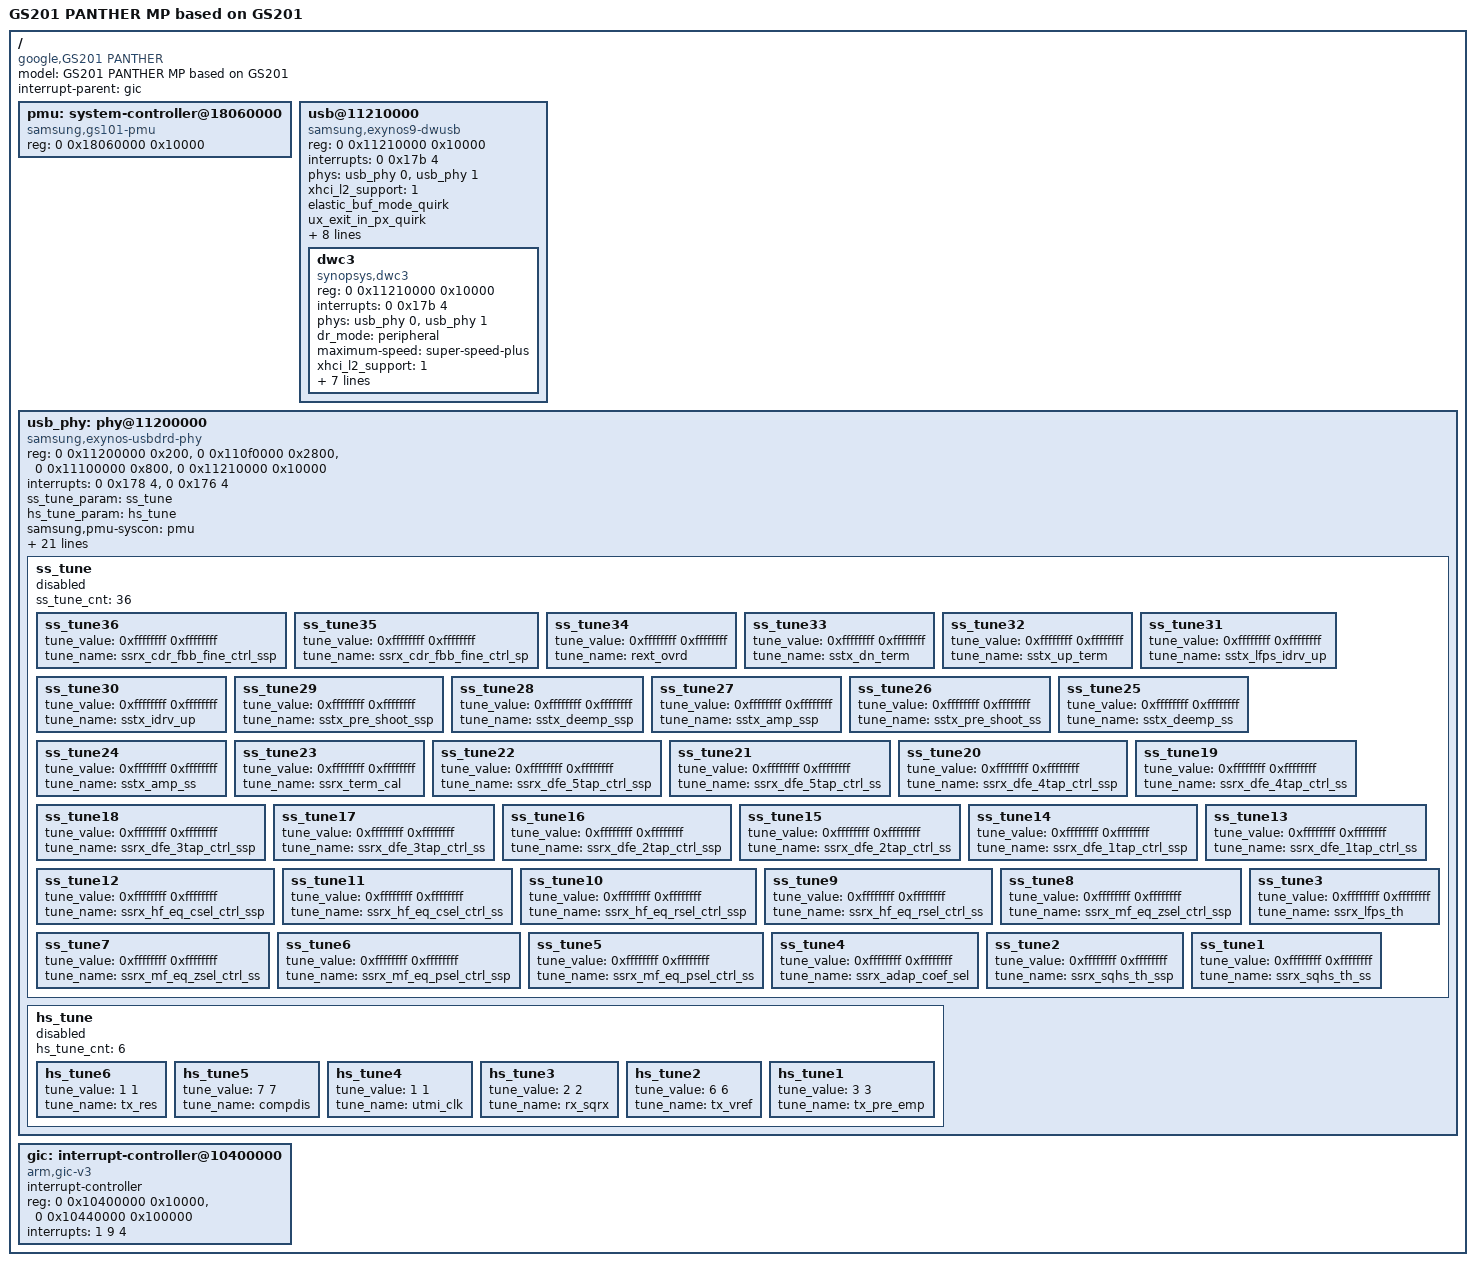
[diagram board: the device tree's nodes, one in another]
/dts-v1/;

/*
 * \brief  Device tree of the USB controller of the Google Pixel 7
 * \author Ivan Loskutov
 * \date   2026-10-28
 *
 * The tree describes what the USB gadget driver needs: the USB controller
 * of the HSI0 block in device mode, its PHYs, the power-management unit,
 * and the interrupt controller. The values are those of the vendor's
 * device tree for the phone (gs201-panther).
 *
 * Left out are references that have no counterpart in the driver's Linux
 * emulation environment: clocks (the drivers get them by name from the
 * platform driver), power domains (switched by the platform driver), the
 * links to the Type-C controller ('extcon', the driver reads the cable
 * orientation itself), the power-supply class ('usb-psy-name', the
 * controller would wait for it), the reserved memory and the S2MPU of the
 * host mode, and the offload of the audio DSP. The isolation of the PHYs in
 * the power-management unit is released by bootstrap.
 */

/*
 * SPDX-License-Identifier: GPL-2.0
 */

/ {
	model = "GS201 PANTHER MP based on GS201";
	#address-cells = <2>;
	#size-cells = <1>;
	compatible = "google,GS201 PANTHER", "google,GS201";
	interrupt-parent = <&gic>;

	pmu: system-controller@18060000 {
		compatible = "samsung,gs101-pmu", "syscon";
		reg = <0 0x18060000 0x10000>;
	};

	usb@11210000 {
		compatible = "samsung,exynos9-dwusb";
		reg = <0 0x11210000 0x10000>;
		#address-cells = <2>;
		#size-cells = <1>;
		ranges;
		interrupts = <0 0x17b 4>;
		clock-names = "aclk", "sclk", "bus";
		phys = <&usb_phy 0>, <&usb_phy 1>;
		phy-names = "usb2-phy", "usb3-phy";
		xhci_l2_support = <1>;
		elastic_buf_mode_quirk;
		ux_exit_in_px_quirk;
		u1u2_exitfail_quirk;
		samsung,no-extra-delay;
		tx-fifo-resize = <0>;
		adj-sof-accuracy = <1>;
		is_not_vbus_pad = <1>;
		enable_sprs_transfer = <1>;
		usb-pm-qos-int = <200000>;
		usb_host_device_timeout = <0x7ff>;

		dwc3 {
			compatible = "synopsys,dwc3";
			reg = <0 0x11210000 0x10000>;
			interrupts = <0 0x17b 4>;
			clock-names = "aclk", "sclk";
			phys = <&usb_phy 0>, <&usb_phy 1>;
			phy-names = "usb2-phy", "usb3-phy";
			dr_mode = "peripheral";
			maximum-speed = "super-speed-plus";
			xhci_l2_support = <1>;
			snps,dis-u2-entry-quirk;
			snps,dis-u1-entry-quirk;
			snps,dis-u2-freeclk-exists-quirk;
			snps,usb2-gadget-lpm-disable;
			snps,lpm-nyet-threshold = <0>;
			snps,has-lpm-erratum;
			snps,quirk-frame-length-adjustment = <0x20>;
		};
	};

	usb_phy: phy@11200000 {
		compatible = "samsung,exynos-usbdrd-phy";
		reg = <0 0x11200000 0x200>,    /* USB 2.0/3.1 PHY */
		      <0 0x110f0000 0x2800>,   /* USBDP combo PHY */
		      <0 0x11100000 0x800>,    /* PHY control */
		      <0 0x11210000 0x10000>;  /* link (DWC3) */
		interrupts = <0 0x178 4>, <0 0x176 4>;
		clock-names = "phy_ref", "aclk";
		#phy-cells = <1>;
		ranges;
		ss_tune_param = <&ss_tune>;
		hs_tune_param = <&hs_tune>;
		samsung,pmu-syscon = <&pmu>;
		pmu_mask = <0>;
		pmu_offset = <0x3eb0>;
		pmu_offset_dp = <0x3eb4>;
		phy_version = <0x301>;
		phyclk_mux = "none";
		phy_refclk = "phy_ref";
		phy_ref_clock = <19200000>;
		has_other_phy = <0>;
		has_combo_phy = <1>;
		sub_phy_version = <0x404>;
		ip_type = <0>;
		phy_refsel_clockcore = <1>;
		phy_refsel_ext_osc = <0>;
		phy_refsel_xtal = <0>;
		phy_refsel_diff_pad = <0>;
		phy_refsel_diff_internal = <0>;
		phy_refsel_diff_single = <0>;
		use_io_for_ovc = <0>;
		common_block_disable = <1>;
		is_not_vbus_pad = <1>;
		used_phy_port = <0>;

		ss_tune: ss_tune {
			ss_tune_cnt = <36>;
			status = "disabled";

			ss_tune36 {
				tune_value = <0xffffffff 0xffffffff>;
				tune_name = "ssrx_cdr_fbb_fine_ctrl_ssp";
			};

			ss_tune35 {
				tune_value = <0xffffffff 0xffffffff>;
				tune_name = "ssrx_cdr_fbb_fine_ctrl_sp";
			};

			ss_tune34 {
				tune_value = <0xffffffff 0xffffffff>;
				tune_name = "rext_ovrd";
			};

			ss_tune33 {
				tune_value = <0xffffffff 0xffffffff>;
				tune_name = "sstx_dn_term";
			};

			ss_tune32 {
				tune_value = <0xffffffff 0xffffffff>;
				tune_name = "sstx_up_term";
			};

			ss_tune31 {
				tune_value = <0xffffffff 0xffffffff>;
				tune_name = "sstx_lfps_idrv_up";
			};

			ss_tune30 {
				tune_value = <0xffffffff 0xffffffff>;
				tune_name = "sstx_idrv_up";
			};

			ss_tune29 {
				tune_value = <0xffffffff 0xffffffff>;
				tune_name = "sstx_pre_shoot_ssp";
			};

			ss_tune28 {
				tune_value = <0xffffffff 0xffffffff>;
				tune_name = "sstx_deemp_ssp";
			};

			ss_tune27 {
				tune_value = <0xffffffff 0xffffffff>;
				tune_name = "sstx_amp_ssp";
			};

			ss_tune26 {
				tune_value = <0xffffffff 0xffffffff>;
				tune_name = "sstx_pre_shoot_ss";
			};

			ss_tune25 {
				tune_value = <0xffffffff 0xffffffff>;
				tune_name = "sstx_deemp_ss";
			};

			ss_tune24 {
				tune_value = <0xffffffff 0xffffffff>;
				tune_name = "sstx_amp_ss";
			};

			ss_tune23 {
				tune_value = <0xffffffff 0xffffffff>;
				tune_name = "ssrx_term_cal";
			};

			ss_tune22 {
				tune_value = <0xffffffff 0xffffffff>;
				tune_name = "ssrx_dfe_5tap_ctrl_ssp";
			};

			ss_tune21 {
				tune_value = <0xffffffff 0xffffffff>;
				tune_name = "ssrx_dfe_5tap_ctrl_ss";
			};

			ss_tune20 {
				tune_value = <0xffffffff 0xffffffff>;
				tune_name = "ssrx_dfe_4tap_ctrl_ssp";
			};

			ss_tune19 {
				tune_value = <0xffffffff 0xffffffff>;
				tune_name = "ssrx_dfe_4tap_ctrl_ss";
			};

			ss_tune18 {
				tune_value = <0xffffffff 0xffffffff>;
				tune_name = "ssrx_dfe_3tap_ctrl_ssp";
			};

			ss_tune17 {
				tune_value = <0xffffffff 0xffffffff>;
				tune_name = "ssrx_dfe_3tap_ctrl_ss";
			};

			ss_tune16 {
				tune_value = <0xffffffff 0xffffffff>;
				tune_name = "ssrx_dfe_2tap_ctrl_ssp";
			};

			ss_tune15 {
				tune_value = <0xffffffff 0xffffffff>;
				tune_name = "ssrx_dfe_2tap_ctrl_ss";
			};

			ss_tune14 {
				tune_value = <0xffffffff 0xffffffff>;
				tune_name = "ssrx_dfe_1tap_ctrl_ssp";
			};

			ss_tune13 {
				tune_value = <0xffffffff 0xffffffff>;
				tune_name = "ssrx_dfe_1tap_ctrl_ss";
			};

			ss_tune12 {
				tune_value = <0xffffffff 0xffffffff>;
				tune_name = "ssrx_hf_eq_csel_ctrl_ssp";
			};

			ss_tune11 {
				tune_value = <0xffffffff 0xffffffff>;
				tune_name = "ssrx_hf_eq_csel_ctrl_ss";
			};

			ss_tune10 {
				tune_value = <0xffffffff 0xffffffff>;
				tune_name = "ssrx_hf_eq_rsel_ctrl_ssp";
			};

			ss_tune9 {
				tune_value = <0xffffffff 0xffffffff>;
				tune_name = "ssrx_hf_eq_rsel_ctrl_ss";
			};

			ss_tune8 {
				tune_value = <0xffffffff 0xffffffff>;
				tune_name = "ssrx_mf_eq_zsel_ctrl_ssp";
			};

			ss_tune7 {
				tune_value = <0xffffffff 0xffffffff>;
				tune_name = "ssrx_mf_eq_zsel_ctrl_ss";
			};

			ss_tune6 {
				tune_value = <0xffffffff 0xffffffff>;
				tune_name = "ssrx_mf_eq_psel_ctrl_ssp";
			};

			ss_tune5 {
				tune_value = <0xffffffff 0xffffffff>;
				tune_name = "ssrx_mf_eq_psel_ctrl_ss";
			};

			ss_tune4 {
				tune_value = <0xffffffff 0xffffffff>;
				tune_name = "ssrx_adap_coef_sel";
			};

			ss_tune3 {
				tune_value = <0xffffffff 0xffffffff>;
				tune_name = "ssrx_lfps_th";
			};

			ss_tune2 {
				tune_value = <0xffffffff 0xffffffff>;
				tune_name = "ssrx_sqhs_th_ssp";
			};

			ss_tune1 {
				tune_value = <0xffffffff 0xffffffff>;
				tune_name = "ssrx_sqhs_th_ss";
			};
		};

		hs_tune: hs_tune {
			hs_tune_cnt = <6>;
			status = "disabled";

			hs_tune6 {
				tune_value = <1 1>;
				tune_name = "tx_res";
			};

			hs_tune5 {
				tune_value = <7 7>;
				tune_name = "compdis";
			};

			hs_tune4 {
				tune_value = <1 1>;
				tune_name = "utmi_clk";
			};

			hs_tune3 {
				tune_value = <2 2>;
				tune_name = "rx_sqrx";
			};

			hs_tune2 {
				tune_value = <6 6>;
				tune_name = "tx_vref";
			};

			hs_tune1 {
				tune_value = <3 3>;
				tune_name = "tx_pre_emp";
			};
		};
	};

	gic: interrupt-controller@10400000 {
		compatible = "arm,gic-v3";
		#interrupt-cells = <3>;
		interrupt-controller;
		reg = <0 0x10400000 0x10000>,
		      <0 0x10440000 0x100000>;
		interrupts = <1 9 4>;
	};
};
